# PIC16F1847 register map
Vendor: Microchip
Registers are 8-bit, read-write, reset 0x0 unless marked. A register's access mark holds for its fields unless they carry their own. Addresses are absolute, and some are shared; only a register's first bit layout is shown; [hi:lo] are bit positions; {n}, {i} and the like mark numbered series; 'fields as' and 'values as' point back to an identical list.

## SFR
0x00 INDF0 reset not defined — (power-on value xxxxxxxx)
0x01 INDF1 reset not defined — (power-on value xxxxxxxx)
0x02 PCL
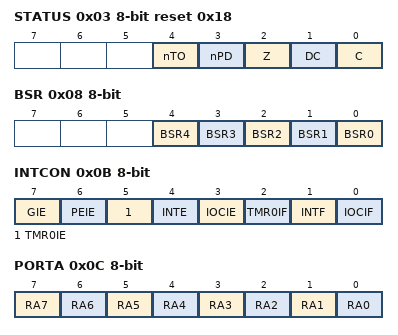
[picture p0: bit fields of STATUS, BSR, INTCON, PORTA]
0x03 STATUS reset 0x18
  [4] nTO ro, [3] nPD ro, [2] Z, [1] DC, [0] C
0x04 FSR0L
0x05 FSR0H
0x06 FSR1L
0x07 FSR1H
0x08 BSR
  [n] BSR{n} (n=0..4)
0x09 WREG
  [7:0] WREG0
0x0A PCLATH
  [6:0] PCLATH
0x0B INTCON
  [7] GIE, [6] PEIE, [5] TMR0IE, [4] INTE, [3] IOCIE, [2] TMR0IF, [1] INTF, [0] IOCIF ro
0x0C PORTA reset not defined — (power-on value xxxxxxxx)
  [7] RA7, [6] RA6, [5] RA5 ro, [n] RA{n} (n=0..4)
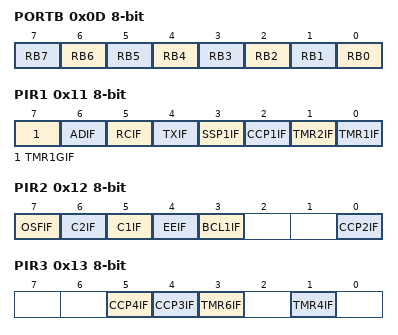
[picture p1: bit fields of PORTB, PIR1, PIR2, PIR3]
0x0D PORTB reset not defined — (power-on value xxxxxxxx)
  [n] RB{n} (n=0..7)
0x11 PIR1
  [7] TMR1GIF — Timer1 Gate Interrupt Flag bit
  [6] ADIF — A/D Converter Interrupt Flag bit
  [5] RCIF ro — EUSART Receive Interrupt Flag bit
  [4] TXIF ro — EUSART Transmit Interrupt Flag bit
  [3] SSP1IF — Master Synchronous Serial Port (MSSP) Interrupt Flag bit
  [2] CCP1IF — CCP1 Interrupt Flag bit
  [1] TMR2IF — TMR2 to PR2 Match Interrupt Flag bit
  [0] TMR1IF — TMR1 Overflow Interrupt Flag bit
0x12 PIR2
  [7] OSFIF, [6] C2IF, [5] C1IF, [4] EEIF, [3] BCL1IF, [0] CCP2IF
0x13 PIR3
  [5] CCP4IF, [4] CCP3IF, [3] TMR6IF, [1] TMR4IF
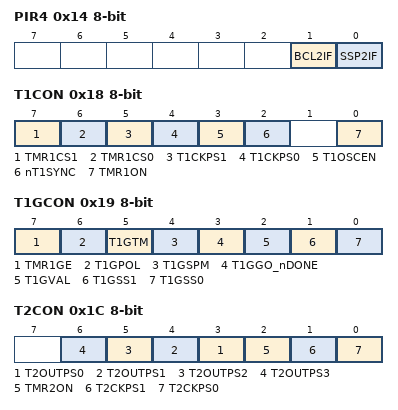
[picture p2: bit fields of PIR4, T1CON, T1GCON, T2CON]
0x14 PIR4
  [1] BCL2IF, [0] SSP2IF
0x15 TMR0 reset not defined — (power-on value xxxxxxxx)
0x16 TMR1L reset not defined — (power-on value xxxxxxxx)
0x17 TMR1H reset not defined — (power-on value xxxxxxxx)
0x18 T1CON
  [7] TMR1CS1, [6] TMR1CS0, [5] T1CKPS1, [4] T1CKPS0, [3] T1OSCEN, [2] nT1SYNC, [0] TMR1ON
0x19 T1GCON reset not defined — (power-on value 00000x00)
  [7] TMR1GE, [6] T1GPOL, [5] T1GTM, [4] T1GSPM, [3] T1GGO_nDONE, [2] T1GVAL ro, [1] T1GSS1, [0] T1GSS0
0x1A TMR2
0x1B PR2 reset 0xFF
0x1C T2CON
  [n+3] T2OUTPS{n} (n=0..3), [2] TMR2ON, [1] T2CKPS1, [0] T2CKPS0
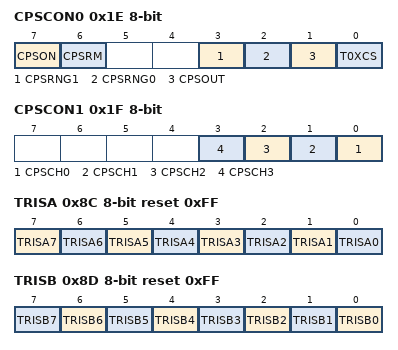
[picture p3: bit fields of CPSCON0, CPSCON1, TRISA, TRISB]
0x1E CPSCON0
  [7] CPSON, [6] CPSRM, [3] CPSRNG1, [2] CPSRNG0, [1] CPSOUT ro, [0] T0XCS
0x1F CPSCON1
  [n] CPSCH{n} (n=0..3)
0x8C TRISA reset 0xFF — PORTA Data Direction Control Register
  [7] TRISA7, [6] TRISA6, [5] TRISA5 ro, [n] TRISA{n} (n=0..4)
0x8D TRISB reset 0xFF — PORTB Data Direction Control Register
  [n] TRISB{n} (n=0..7)
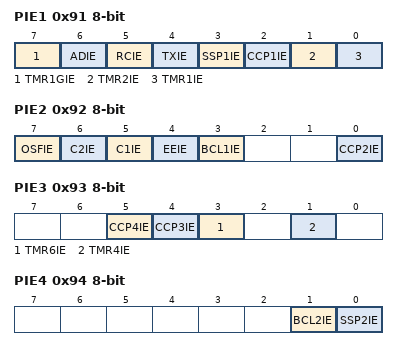
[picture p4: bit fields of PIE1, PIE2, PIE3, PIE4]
0x91 PIE1 — Peripheral Interrupt Enable Register 1
  [7] TMR1GIE — Timer1 Gate Interrupt Enable bit
  [6] ADIE — A/D Converter Interrupt Enable bit
  [5] RCIE — EUSART Receive Interrupt Enable bit
  [4] TXIE — EUSART Transmit Interrupt Enable bit
  [3] SSP1IE — Master Synchronous Serial Port (MSSP) Interrupt Enable bit
  [2] CCP1IE — CCP1 Interrupt Enable bit
  [1] TMR2IE — TMR2 to PR2 Match Interrupt Enable bit
  [0] TMR1IE — TMR1 Overflow Interrupt Enable bit
0x92 PIE2 — Peripheral Interrupt Enable Register 2
  [7] OSFIE — CCP2 Interrupt Enable bit
  [6] C2IE — Comparator C2 Interrupt Enable bit
  [5] C1IE — Comparator C1 Interrupt Enable bit
  [4] EEIE — EEPROM Write Completion Interrupt Enable bit
  [3] BCL1IE — MSSP Bus Collision Interrupt Interrupt Enable bit
  [0] CCP2IE — CCP2 Interrupt Enable bit
0x93 PIE3 — Peripheral Interrupt Enable Register 3
  [5] CCP4IE — CCP4 Interrupt Enable bit
  [4] CCP3IE — CCP3 Interrupt Enable bit
  [3] TMR6IE — TMR6 to PR6 Match Interrupt Enable bit
  [1] TMR4IE — TMR4 to PR4 Match Interrupt Enable bit
0x94 PIE4 — Peripheral Interrupt Enable Register 4
  [1] BCL2IE, [0] SSP2IE
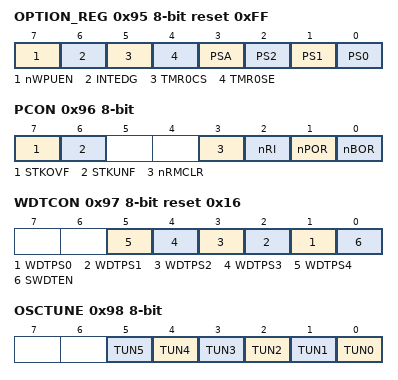
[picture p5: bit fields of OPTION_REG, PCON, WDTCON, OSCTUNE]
0x95 OPTION_REG reset 0xFF — Option Register
  [7] nWPUEN — Weak Pull-up Enable bit
  [6] INTEDG — Interrupt Edge Select bit
  [5] TMR0CS — TMR0 Clock Source Select bit
  [4] TMR0SE — TMR0 Source Edge Select bit
  [3] PSA — Prescaler Active bit
  [2] PS2 — Prescaler Rate Select bits
  [1] PS1 — Prescaler Rate Select bits
  [0] PS0 — Prescaler Rate Select bits
0x96 PCON reset not defined — Power Control Register (power-on value 00--11qq)
  [7] STKOVF — Stack Overflow Flag bit
  [6] STKUNF — Stack Underflow Flag bit
  [3] nRMCLR — MCLR Reset Flag bit
  [2] nRI — RESET Instruction Flag bit
  [1] nPOR — Power-on Reset Status bit
  [0] nBOR — Brown-out Reset Status bit
0x97 WDTCON reset 0x16 — Watchdog Timer Control Register
  [n+1] WDTPS{n} (n=0..4) — Watchdog Timer Period Select bits
  [0] SWDTEN — Software Enable/Disable for Watch Dog Timer bit
0x98 OSCTUNE — Oscillator Tuning Register
  [n] TUN{n} (n=0..5) — Frequency Tuning bits
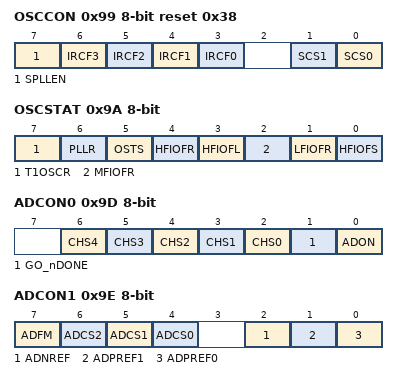
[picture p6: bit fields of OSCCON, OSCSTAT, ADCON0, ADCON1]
0x99 OSCCON reset 0x38 — Oscillator Control Register
  [7] SPLLEN — Software PLL Enable bit
  [n+3] IRCF{n} (n=0..3) — Internal Oscillator Frequency Select bits
  [1] SCS1 — System clock select bit
  [0] SCS0 — System clock select bit
0x9A OSCSTAT ro reset not defined — Oscillator Status Register (power-on value 00q00q00)
  [7] T1OSCR — Timer1 Oscillator Ready bit
  [6] PLLR — 4x PLL Ready bit
  [5] OSTS — Oscillator Start-up Time-out Status bit
  [4] HFIOFR — High Freqency Internal Oscillator Ready bit
  [3] HFIOFL — High Freqency Internal Oscillator Status Locked bit
  [2] MFIOFR — Medium Freqency Internal Oscillator Ready bit
  [1] LFIOFR — Low Freqency Internal Oscillator Ready bit
  [0] HFIOFS — Low Freqency Internal Oscillator Ready bit
0x9B ADRESL reset not defined — A/D Result Register LSB (power-on value xxxxxxxx)
0x9C ADRESH reset not defined — A/D Result Register MSB (power-on value xxxxxxxx)
0x9D ADCON0 — Analog-to-Digital Control Register 0
  [n+2] CHS{n} (n=0..4) — Analog Channel Select bits
  [1] GO_nDONE — A/D Conversion Status bit
  [0] ADON — A/D Module Enable bit
0x9E ADCON1 — Analog-to-Digital Control Register 1
  [7] ADFM — A/D Result Format Select bit
  [6] ADCS2 — A/D Conversion Clock Select bits
  [5] ADCS1 — A/D Conversion Clock Select bits
  [4] ADCS0 — A/D Conversion Clock Select bits
  [2] ADNREF — A/D Negative Voltage Reference Configuration
  [1] ADPREF1 — A/D Positive Voltage Reference Configuration
  [0] ADPREF0 — A/D Positive Voltage Reference Configuration
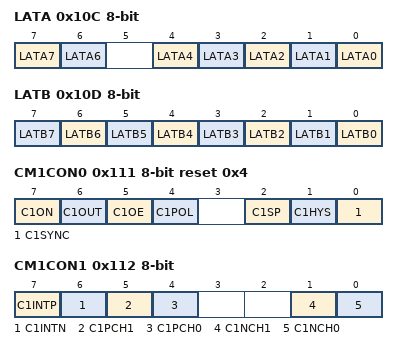
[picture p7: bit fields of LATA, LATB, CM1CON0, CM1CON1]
0x10C LATA reset not defined — (power-on value xx-xxxxx)
  [7] LATA7, [6] LATA6, [n] LATA{n} (n=0..4)
0x10D LATB reset not defined — (power-on value xxxxxxxx)
  [n] LATB{n} (n=0..7)
0x111 CM1CON0 reset 0x4
  [7] C1ON — Comparator Enable bit
  [6] C1OUT ro — Comparator Output bit
  [5] C1OE — Comparator Output Enable bit
  [4] C1POL — Comparator Output Polarity Select bit
  [2] C1SP — Comparator Speed/Power Select bit
  [1] C1HYS — Comparator Hysteresis Enable bit
  [0] C1SYNC — Comparator Output Synchronous Mode bit
0x112 CM1CON1
  [7] C1INTP — Comparator Interrupt on Positive going edge Enable bits
  [6] C1INTN — Comparator Interrupt on Negative going edge Enable bits
  [5] C1PCH1 — Comparator Positive Input Channel Select bits
  [4] C1PCH0 — Comparator Positive Input Channel Select bits
  [1] C1NCH1 — Comparator Negative Input Channel Select bits
  [0] C1NCH0 — Comparator Negative Input Channel Select bits
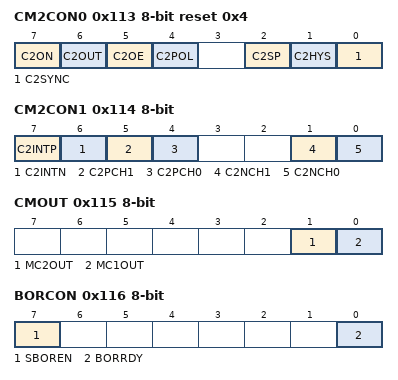
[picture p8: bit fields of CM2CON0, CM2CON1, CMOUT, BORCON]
0x113 CM2CON0 reset 0x4
  [7] C2ON, [6] C2OUT ro, [5] C2OE, [4] C2POL, [2] C2SP, [1] C2HYS, [0] C2SYNC
0x114 CM2CON1
  [7] C2INTP — Comparator Interrupt on Positive going edge Enable bits
  [6] C2INTN — Comparator Interrupt on Negative going edge Enable bits
  [5] C2PCH1 — Comparator Positive Input Channel Select bits
  [4] C2PCH0 — Comparator Positive Input Channel Select bits
  [1] C2NCH1 — Comparator Negative Input Channel Select bits
  [0] C2NCH0 — Comparator Negative Input Channel Select bits
0x115 CMOUT ro — Comparator Output Register
  [1] MC2OUT, [0] MC1OUT
0x116 BORCON reset not defined — Brown-out Reset Control Register (power-on value 1------q)
  [7] SBOREN — Software Brown Out Reset Enable bit
  [0] BORRDY ro — Brown-out Reset Circuit Ready Status bit
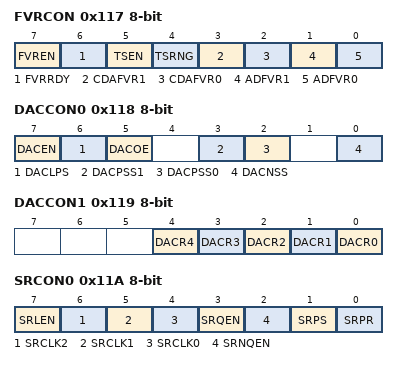
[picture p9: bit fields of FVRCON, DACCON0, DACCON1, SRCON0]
0x117 FVRCON reset not defined — Fixed Voltage Reference Control Register (power-on value 0q000000)
  [7] FVREN — Fixed Voltage Reference Enable
  [6] FVRRDY ro — Fixed Voltage Reference Ready Flag
  [5] TSEN — Temperature Indicator Enable
  [4] TSRNG — Temperature Indicator Range Selection
  [3] CDAFVR1 — Comparator and D/A Converter Fixed Voltage Reference Selection
  [2] CDAFVR0 — Comparator and D/A Converter Fixed Voltage Reference Selection
  [1] ADFVR1 — A/D Converter Fixed Voltage Reference Selection
  [0] ADFVR0 — A/D Converter Fixed Voltage Reference Selection
0x118 DACCON0 — Voltage Reference Control Register 0
  [7] DACEN — DAC 1 Enable bit
  [6] DACLPS — DAC 1 Low Power Voltage State Select bit
  [5] DACOE — DAC1 Voltage Output Enable bit
  [3] DACPSS1 — DAC1 Positive Source Select bits
  [2] DACPSS0 — DAC1 Positive Source Select bits
  [0] DACNSS — DAC1 Negative Source Select bits
0x119 DACCON1 — Voltage Reference Control Register 1
  [n] DACR{n} (n=0..4) — DAC1 Voltage Output Select bits
0x11A SRCON0 — SR Latch Control Register 0
  [7] SRLEN — SR Latch Enable bit
  [6] SRCLK2 — SR Latch Clock divider bits
  [5] SRCLK1 — SR Latch Clock divider bits
  [4] SRCLK0 — SR Latch Clock divider bits
  [3] SRQEN — SR Latch Q Output Enable bit
  [2] SRNQEN — SR Latch Q Output Enable bit
  [1] SRPS — Pulse Set Input of the SR Latch
  [0] SRPR — Pulse Reset Input of the SR Latch
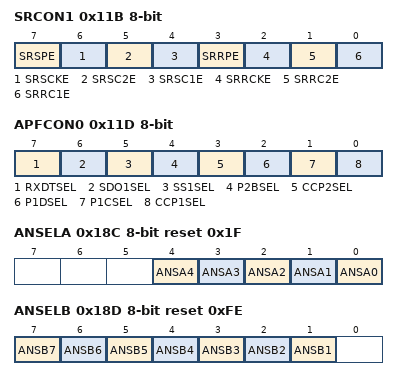
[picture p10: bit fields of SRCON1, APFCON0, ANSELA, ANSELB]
0x11B SRCON1 — SR Latch Control Register 1
  [7] SRSPE — SR Latch Peripheral Set Enable bit
  [6] SRSCKE — SR Latch Set Clock Enable bit
  [5] SRSC2E — SR Latch C2 Set Enable bit
  [4] SRSC1E — SR Latch C1 Set Enable bit
  [3] SRRPE — SR Latch Peripheral Reset Enable bit
  [2] SRRCKE — SR Latch Reset Clock Enable bit
  [1] SRRC2E — SR Latch C2 Reset Enable bit
  [0] SRRC1E — SR Latch C1 Reset Enable bit
0x11D APFCON0 — Alternate Pin Function Control Register
  [7] RXDTSEL
  [6] SDO1SEL — CCP3 Input/Output Pin Selection
  [5] SS1SEL — Timer1 Gate Input Pin Selection
  [4] P2BSEL — CCP2 PWM B Output Pin Selection
  [3] CCP2SEL — SR Latch nQ Output Pin Selection
  [2] P1DSEL — Comparator 2 Output Pin Selection
  [1] P1CSEL — SS Input Pin Selection
  [0] CCP1SEL — CCP2 Input/Output Pin Selection
0x11E APFCON1
  [0] TXCKSEL
0x18C ANSELA reset 0x1F
  [n] ANSA{n} (n=0..4)
0x18D ANSELB reset 0xFE
  [n] ANSB{n} (n=1..7)
0x191 EEADRL
0x192 EEADRH reset 0x80
  [6:0] EEADRH
0x193 EEDATL reset not defined — (power-on value xxxxxxxx)
0x194 EEDATH reset not defined — (power-on value --xxxxxx)
  [5:0] EEDATH
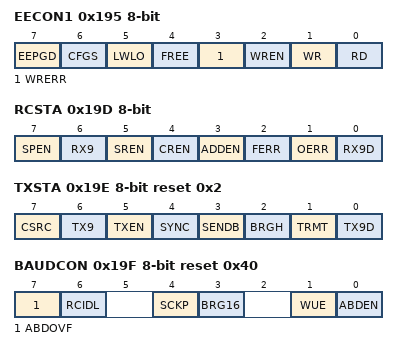
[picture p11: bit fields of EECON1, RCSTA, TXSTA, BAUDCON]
0x195 EECON1 reset not defined — (power-on value 0000x000)
  [7] EEPGD — FLASH Program / Data EEPROM Memory Select bit
  [6] CFGS — FLASH Program / Data EEPROM or Configuration Select bit
  [5] LWLO — Load Write Latches Only bit
  [4] FREE — Program FLASH Erase Enable bit
  [3] WRERR — Sequence Error Flag bit
  [2] WREN — Program/Erase Enable bit
  [1] WR — Write Control bit (can only be set)
  [0] RD — Read Control bit (can only be set)
0x196 EECON2 wo reset not defined
0x199 RCREG ro
0x19A TXREG
0x19B SP1BRGL
  [7:0] SPBRGL
0x19C SP1BRGH
  [7:0] SPBRGH
0x19D RCSTA reset not defined — Receive Status and Control Register (power-on value 0000000x)
  [7] SPEN — Serial Port Enable bit
  [6] RX9 — 9-bit Receive Enable bit
  [5] SREN — Single Receive Enable bit
  [4] CREN — Continuous Receive Enable bit
  [3] ADDEN — Address Detect Enable bit
  [2] FERR ro — Framing Error bit
  [1] OERR ro — Overrun Error bit
  [0] RX9D ro — 9th bit of received data (can be parity bit)
0x19E TXSTA reset 0x2 — Transmit Status and Control Register
  [7] CSRC — Clock Source Select bit
  [6] TX9 — 9-bit Transmit Enable bit
  [5] TXEN — Transmit Enable bit
  [4] SYNC — USART Mode Select bit
  [3] SENDB — Send BREAK character bit
  [2] BRGH — High Baud Rate Select bit
  [1] TRMT ro — Transmit Operation Idle Status bit
  [0] TX9D — 9th bit of transmit data; can be used as parity bit
0x19F BAUDCON reset 0x40 — Baud Rate Control Register
  [7] ABDOVF — BRG Rollover Status bit
  [6] RCIDL ro — Receive Operation Idle Status bit
  [4] SCKP — Clock/Transmit Polarity Select bit
  [3] BRG16 — 16-bit Baud Rate Register enable bit
  [1] WUE — Wake-Up Enable bit
  [0] ABDEN — Auto-Baud Detect Enable bit
0x20C WPUA reset 0x20
  [5] WPUA5
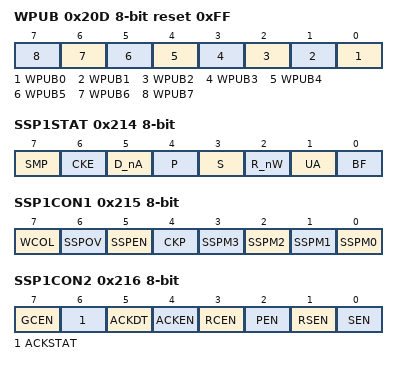
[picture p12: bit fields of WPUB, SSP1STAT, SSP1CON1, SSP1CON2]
0x20D WPUB reset 0xFF
  [n] WPUB{n} (n=0..7)
0x211 SSP1BUF reset not defined — (power-on value xxxxxxxx)
  [7:0] SSPBUF
0x212 SSP1ADD
  [7:0] SSPADD
0x213 SSP1MSK reset 0xFF
  [7:0] SSPMSK
0x214 SSP1STAT
  [7] SMP, [6] CKE, [5] D_nA ro, [4] P ro, [3] S ro, [2] R_nW ro, [1] UA ro, [0] BF ro
0x215 SSP1CON1 reset not defined — (power-on value 0000xxxx)
  [7] WCOL, [6] SSPOV, [5] SSPEN, [4] CKP, [n] SSPM{n} (n=0..3)
0x216 SSP1CON2
  [7] GCEN, [6] ACKSTAT ro, [5] ACKDT, [4] ACKEN, [3] RCEN, [2] PEN, [1] RSEN, [0] SEN
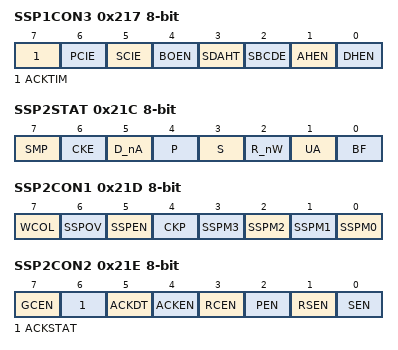
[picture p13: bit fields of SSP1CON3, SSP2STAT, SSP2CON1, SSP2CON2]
0x217 SSP1CON3
  [7] ACKTIM ro, [6] PCIE, [5] SCIE, [4] BOEN, [3] SDAHT, [2] SBCDE, [1] AHEN, [0] DHEN
0x219 SSP2BUF reset not defined — (power-on value xxxxxxxx)
  [7:0] SSPBUF
0x21A SSP2ADD
  [7:0] SSPADD
0x21B SSP2MSK reset 0xFF
  [7:0] SSPMSK
0x21C SSP2STAT
  fields as SSP1STAT
0x21D SSP2CON1 reset not defined — (power-on value 0000xxxx)
  [7] WCOL, [6] SSPOV, [5] SSPEN, [4] CKP, [n] SSPM{n} (n=0..3)
0x21E SSP2CON2
  fields as SSP1CON2
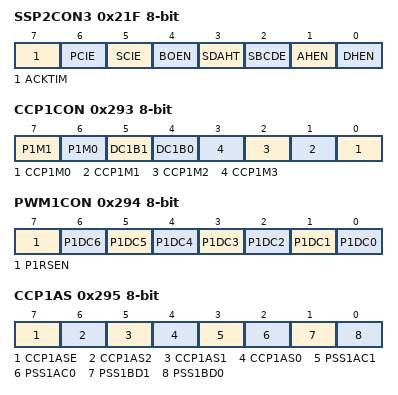
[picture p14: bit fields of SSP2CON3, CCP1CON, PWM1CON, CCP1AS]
0x21F SSP2CON3
  fields as SSP1CON3
0x291 CCPR1L reset not defined — (power-on value xxxxxxxx)
0x292 CCPR1H reset not defined — (power-on value xxxxxxxx)
0x293 CCP1CON
  [7] P1M1, [6] P1M0, [5] DC1B1, [4] DC1B0, [n] CCP1M{n} (n=0..3)
0x294 PWM1CON
  [7] P1RSEN, [n] P1DC{n} (n=0..6)
0x295 CCP1AS
  [7] CCP1ASE, [6] CCP1AS2, [5] CCP1AS1, [4] CCP1AS0, [3] PSS1AC1, [2] PSS1AC0, [1] PSS1BD1, [0] PSS1BD0
0x296 PSTR1CON reset 0x1
  [4] STR1SYNC, [3] STR1D, [2] STR1C, [1] STR1B, [0] STR1A
0x298 CCPR2L reset not defined — (power-on value xxxxxxxx)
0x299 CCPR2H reset not defined — (power-on value xxxxxxxx)
0x29A CCP2CON
  [7] P2M1, [6] P2M0, [5] DC2B1, [4] DC2B0, [n] CCP2M{n} (n=0..3)
0x29B PWM2CON
  [7] P2RSEN, [n] P2DC{n} (n=0..6)
0x29C CCP2AS
  [7] CCP2ASE, [6] CCP2AS2, [5] CCP2AS1, [4] CCP2AS0, [3] PSS2AC1, [2] PSS2AC0, [1] PSS2BD1, [0] PSS2BD0
0x29D PSTR2CON reset 0x1
  [4] STR2SYNC, [3] STR2D, [2] STR2C, [1] STR2B, [0] STR2A
0x29E CCPTMRS
  [2n-1] C{n}TSEL1 (n=1..4), [2n-2] C{n}TSEL0 (n=1..4)
0x311 CCPR3L reset not defined — (power-on value xxxxxxxx)
0x312 CCPR3H reset not defined — (power-on value xxxxxxxx)
0x313 CCP3CON
  [5] DC3B1, [4] DC3B0, [n] CCP3M{n} (n=0..3)
0x318 CCPR4L reset not defined — (power-on value xxxxxxxx)
0x319 CCPR4H reset not defined — (power-on value xxxxxxxx)
0x31A CCP4CON
  [5] DC4B1, [4] DC4B0, [n] CCP4M{n} (n=0..3)
0x394 IOCBP — Interrupt-On-Change Positive Edge Register
  [n] IOCBP{n} (n=0..7)
0x395 IOCBN — Interrupt-On-Change Negative Edge Register
  [n] IOCBN{n} (n=0..7)
0x396 IOCBF — Interrupt-On-Change Flag Register
  [n] IOCBF{n} (n=0..7)
0x39A CLKRCON reset 0x30
  [7] CLKREN, [6] CLKROE, [5] CLKRSLR, [4] CLKRDC1, [3] CLKRDC0, [2] CLKRDIV2, [1] CLKRDIV1, [0] CLKRDIV0
0x39C MDCON reset 0x20
  [7] MDEN, [6] MDOE, [5] MDSLR, [4] MDOPOL, [3] MDOUT ro, [0] MDBIT
0x39D MDSRC reset not defined — (power-on value x---xxxx)
  [7] MDMSODIS, [n] MDMS{n} (n=0..3)
0x39E MDCARL reset not defined — (power-on value xxx-xxxx)
  [7] MDCLODIS, [6] MDCLPOL, [5] MDCLSYNC, [n] MDCL{n} (n=0..3)
0x39F MDCARH reset not defined — (power-on value xxx-xxxx)
  [7] MDCHODIS, [6] MDCHPOL, [5] MDCHSYNC, [n] MDCH{n} (n=0..3)
0x415 TMR4
0x416 PR4 reset 0xFF
0x417 T4CON — Timer2 Control Register
  [n+3] T4OUTPS{n} (n=0..3) — Timer2 Output Postscaler Select bits
  [2] TMR4ON — Timer2 On bit
  [1] T4CKPS1 — Timer2 Clock Prescale Select bits
  [0] T4CKPS0 — Timer2 Clock Prescale Select bits
0x41C TMR6
0x41D PR6 reset 0xFF
0x41E T6CON — Timer2 Control Register
  [n+3] T6OUTPS{n} (n=0..3) — Timer2 Output Postscaler Select bits
  [2] TMR6ON — Timer2 On bit
  [1] T6CKPS1 — Timer2 Clock Prescale Select bits
  [0] T6CKPS0 — Timer2 Clock Prescale Select bits
0xFE4 STATUS_SHAD reset not defined — (power-on value -----xxx)
  [2] Z_SHAD, [1] DC_SHAD, [0] C_SHAD
0xFE5 WREG_SHAD reset not defined — (power-on value xxxxxxxx)
0xFE6 BSR_SHAD reset not defined — (power-on value ---xxxxx)
  [4:0] BSR_SHAD
0xFE7 PCLATH_SHAD reset not defined — (power-on value -xxxxxxx)
  [6:0] PCLATH_SHAD
0xFE8 FSR0L_SHAD reset not defined — (power-on value xxxxxxxx)
0xFE9 FSR0H_SHAD reset not defined — (power-on value xxxxxxxx)
0xFEA FSR1L_SHAD reset not defined — (power-on value xxxxxxxx)
0xFEB FSR1H_SHAD reset not defined — (power-on value xxxxxxxx)
0xFED STKPTR reset 0x1F — Current Stack pointer
  [4:0] STKPTR
0xFEE TOSL reset not defined — Top of Stack Low byte (power-on value xxxxxxxx)
0xFEF TOSH reset not defined — Top of Stack High byte (power-on value -xxxxxxx)
  [6:0] TOSH
